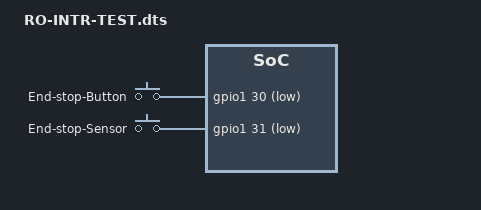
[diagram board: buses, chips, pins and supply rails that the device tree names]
/dts-v1/;
/plugin/;

/{
    compatible = "ti,beaglebone", "ti,beaglebone-black";

    /* identification */
    part-number = "RO-INTR-TEST";
    version = "00A0";
    
    fragment@0 {
        target = <&am33xx_pinmux>;
        __overlay__ {
            end_stop_pins: pinmux_end_stop_pins{
                pinctrl-single,pins = <
                    0x070 0x37  /* P9_11 30 INPUT  MODE7 - Button */
                    0x074 0x2f  /* P9_13 31 INPUT  MODE7 - Sensor */
            	    
            	    /* OUTPUT  GPIO(mode7) 0x07 pulldown, 0x17 pullup, 0x?f no pullup/down */
            	    /* INPUT   GPIO(mode7) 0x27 pulldown, 0x37 pullup, 0x?f no pullup/down */
            	
            	>;
            };
        };
    };

    fragment@1 {
        target = <&ocp>;
        __overlay__ {
            #address-cells=<1>;
            #size-cells=<1>;

            gpio_keys {
                compatible = "gpio-keys";
                pinctrl-names = "default";
                pinctrl-0 = <&end_stop_pins>;
                #address-cells = <1>;
                #size-cells = <0>;

                switch_1 {
                    label = "End-stop-Button";
                    debounce_interval = <50>;
                    linux,code = <1>;
                    gpios = <&gpio1 30 0x5>;
		    gpio-key,wakeup; 
                };

		switch_2 {
                    label = "End-stop-Sensor";
                    debounce_interval = <10>;
                    linux,code = <2>;
                    gpios = <&gpio1 31 0x5>;
                    gpio-key,wakeup;
                };
            };
	};
    };
};
